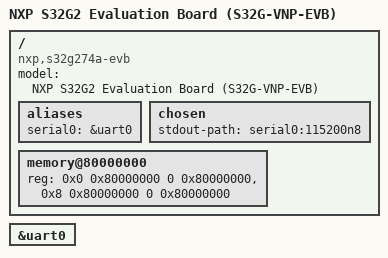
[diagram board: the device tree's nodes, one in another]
/dts-v1/;
#include "s32g2.dtsi"
/ {
	model = "NXP S32G2 Evaluation Board (S32G-VNP-EVB)";
	compatible = "nxp,s32g274a-evb", "nxp,s32g2";
	aliases {
		serial0 = &uart0;
	};
	chosen {
		stdout-path = "serial0:115200n8";
	};
	memory@80000000 {
		device_type = "memory";
		reg = <0x0 0x80000000 0 0x80000000>,
		      <0x8 0x80000000 0 0x80000000>;
	};
};
&uart0 {
	status = "okay";
};
